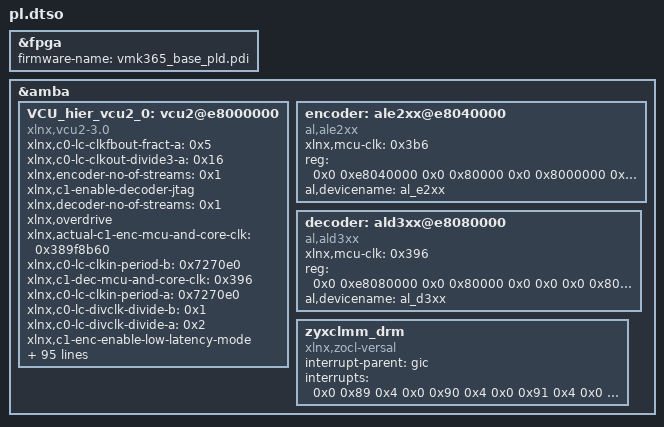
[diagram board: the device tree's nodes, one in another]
/dts-v1/;
/plugin/;

&fpga {
        firmware-name = "vmk365_base_pld.pdi";
};

&amba {

        VCU_hier_vcu2_0: vcu2@e8000000 {
                xlnx,c0-lc-clkfbout-fract-a = <0x5>;
                xlnx,c0-lc-clkout-divide3-a = <0x16>;
                #clock-cells = <0x1>;
                xlnx,encoder-no-of-streams = <0x1>;
                xlnx,c1-enable-decoder-jtag;
                xlnx,decoder-no-of-streams = <0x1>;
                xlnx,overdrive;
                xlnx,actual-c1-enc-mcu-and-core-clk = <0x389f8b60>;
                xlnx,c0-lc-clkin-period-b = <0x7270e0>;
                xlnx,c1-dec-mcu-and-core-clk = <0x396>;
                xlnx,c0-lc-clkin-period-a = <0x7270e0>;
                xlnx,c0-lc-divclk-divide-b = <0x1>;
                xlnx,c0-lc-divclk-divide-a = <0x2>;
                xlnx,c1-enc-enable-low-latency-mode;
                xlnx,decoder-resolution = "4096X2160";
                xlnx,c0-enc-frame-size = <0x5>;
                xlnx,c0-dec-enable-low-latency-mode;
                xlnx,c1-enc-color-depth = <0x2>;
                xlnx,decoder-coding-standard = "HEVC";
                xlnx,c0-enc-color-depth = <0x2>;
                xlnx,c0-no-of-dec-streams = <0x1>;
                xlnx,c0-hdl-dec-enable-low-latency-mode = <0x0>;
                xlnx,c0-enable-decoder;
                xlnx,c0-lc-clkout-divide2-b = <0x3>;
                xlnx,c1-enc-video-standard = <0x0>;
                xlnx,c0-lc-clkout-divide2-a = <0x4>;
                xlnx,c1-enable-encoder-jtag;
                xlnx,c1-enc-coding-type = <0x0>;
                xlnx,c1-enc-frame-size = <0x5>;
                xlnx,c0-enc-coding-type = <0x0>;
                xlnx,c1-enc-mcu-and-core-clk = <0x3b6>;
                xlnx,encoder-color-depth = <0xc>;
                xlnx,nsu-only;
                xlnx,edk-iptype = "PERIPHERAL";
                xlnx,c1-dec-fps = <0x3>;
                xlnx,c1-enable-decoder;
                xlnx,decoder-frame-per-second = <0x3c>;
                xlnx,c0-dec-fps = <0x3>;
                xlnx,decoder-color-format = <0x1bc>;
                xlnx,c1-dec-color-format = <0x3>;
                xlnx,c1-no-of-enc-streams = <0x1>;
                xlnx,c0-dec-frame-size = <0x5>;
                xlnx,design-topology = <0x0>;
                xlnx,c1-enable-seperate-interrupts;
                xlnx,actual-c0-dec-mcu-and-core-clk = <0x36b6ce30>;
                xlnx,enable-instance0-dpll;
                xlnx,name = "VCU_hier_vcu2_0";
                xlnx,c0-lc-clkout-divide1-b = <0x9>;
                xlnx,actual-c0-axi-slave-clk = <0x9f2b120>;
                xlnx,c1-dec-video-standard = <0x0>;
                xlnx,num-of-instances = <0x1>;
                xlnx,c0-dec-color-format = <0x3>;
                xlnx,c0-enable-decoder-jtag;
                xlnx,c1-dec-frame-size = <0x5>;
                xlnx,c1-ref-clk = <0x7f27450>;
                xlnx,encoder-frame-per-second = <0x3c>;
                xlnx,c0-lc-clkfbout-mult-b = <0x15>;
                xlnx,c0-ref-clk = <0x7f27450>;
                xlnx,target-board = <0x0>;
                xlnx,new-param-for-image = <0x0>;
                xlnx,c0-lc-clkfbout-mult-a = <0x37>;
                xlnx,c0-hdl-enable-decoder-jtag = <0x0>;
                xlnx,encoder-color-format = <0x1bc>;
                xlnx,c0-axi-slave-clk = <0xa7>;
                xlnx,c1-enc-color-format = <0x3>;
                xlnx,c0-enc-video-standard = <0x0>;
                xlnx,c0-enc-enable-low-latency-mode;
                xlnx,c1-dec-enable-low-latency-mode;
                xlnx,encoder-coding-standard = "HEVC";
                xlnx,encoder-frequency = <0x3b6>;
                xlnx,c0-no-of-enc-streams = <0x1>;
                xlnx,c0-hdl-encoder-en = <0x1>;
                xlnx,c0-hdl-enc-enable-low-latency-mode = <0x0>;
                xlnx,decoder-frequency = <0x41a>;
                xlnx,c0-enable-encoder;
                xlnx,actual-c0-enc-mcu-and-core-clk = <0x389f8b60>;
                xlnx,c0-dec-mcu-and-core-clk = <0x396>;
                xlnx,c1-dec-color-depth = <0x2>;
                xlnx,c1-enc-source-format = <0x0>;
                xlnx,c0-dec-color-depth = <0x2>;
                compatible = "xlnx,vcu2-3.0";
                xlnx,enable-instance1 = <0x1>;
                xlnx,actual-c1-axi-slave-clk = <0x9f2b120>;
                xlnx,c0-enc-color-format = <0x3>;
                xlnx,c0-lc-clkout-divide0-b = <0x9>;
                xlnx,c0-enable-encoder-jtag;
                xlnx,c1-dec-coding-type = <0x0>;
                xlnx,c1-enable-encoder;
                xlnx,c1-enc-fps = <0x3>;
                xlnx,c0-hdl-enable-encoder-jtag = <0x0>;
                xlnx,c0-enc-fps = <0x3>;
                xlnx,c0-dec-coding-type = <0x0>;
                xlnx,decoder-color-depth = <0xc>;
                xlnx,actual-c1-dec-mcu-and-core-clk = <0x36b6ce30>;
                xlnx,enable-instance1-dpll;
                #address-cells = <0x2>;
                xlnx,c0-enable-seperate-interrupts;
                xlnx,c1-axi-slave-clk = <0xa7>;
                xlnx,encoder-resolution = "4096X2160";
                reg = <0x0 0xe8000000 0x0 0x100000 0x0 0xe8100000 0x0 0x100000>;
                #size-cells = <0x2>;
                xlnx,ip-name = "vcu2";
                xlnx,c0-dec-video-standard = <0x0>;
                xlnx,c0-enc-mcu-and-core-clk = <0x3b6>;
                xlnx,c1-no-of-dec-streams = <0x1>;
                xlnx,c0-hdl-decoder-en = <0x1>;
                xlnx,c0-lc-clkfbout-fract-b = <0x18>;
                xlnx,c0-enc-source-format = <0x0>;
        };

        encoder: ale2xx@e8040000 {
                reg-names = "regs", "apb";
                xlnx,mcu-clk = <0x3b6>;
                reg = <0x0 0xe8040000 0x0 0x80000 0x0 0x8000000 0x0 0x8000000>;
                al,devicename = "al_e2xx";
                clock-names = "mcu";
                compatible = "al,ale2xx";
        };

        decoder: ald3xx@e8080000 {
                reg-names = "regs", "apb";
                xlnx,mcu-clk = <0x396>;
                reg = <0x0 0xe8080000 0x0 0x80000 0x0 0x0 0x0 0x8000000>;
                al,devicename = "al_d3xx";
                clock-names = "mcu";
                compatible = "al,ald3xx";
        };

        zyxclmm_drm {
                compatible = "xlnx,zocl-versal";
                interrupt-parent = <&gic>;
                interrupts = <0x0 0x89 0x4 0x0 0x90 0x4 0x0 0x91 0x4 0x0 0x92 0x4 0x0 0x93 0x4 0x0 0x94 0x4 0x0 0x95 0x4 0x0 0x96 0x4>;
        };
};

